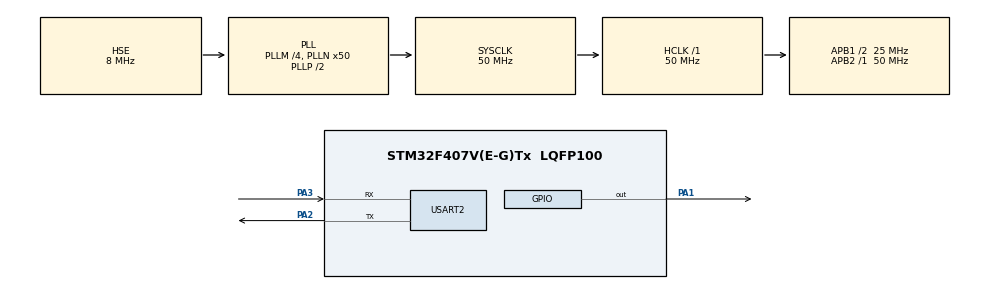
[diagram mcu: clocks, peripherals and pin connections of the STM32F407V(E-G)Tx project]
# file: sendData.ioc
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Mcu.Family=STM32F4
RCC.PLLSourceVirtual=RCC_PLLSOURCE_HSE
PH0-OSC_IN.Signal=RCC_OSC_IN
RCC.CortexFreq_Value=50000000
TIM6.Prescaler=50-1
VP_TIM6_VS_ClockSourceINT.Mode=Enable_Timer
RCC.APB1CLKDivider=RCC_HCLK_DIV2
RCC.SYSCLKSource=RCC_SYSCLKSOURCE_PLLCLK
ProjectManager.StackSize=0x400
PA3.Mode=Asynchronous
ProjectManager.TargetToolchain=STM32CubeIDE
RCC.HCLKFreq_Value=50000000
RCC.APB2TimFreq_Value=50000000
RCC.LSE_VALUE=32768
PA1.Signal=GPIO_Output
RCC.AHBFreq_Value=50000000
PH0-OSC_IN.Mode=HSE-External-Oscillator
RCC.HSE_VALUE=8000000
board=custom
RCC.VCOOutputFreq_Value=100000000
RCC.APB2Freq_Value=50000000
PH1-OSC_OUT.Signal=RCC_OSC_OUT
TIM6.Period=0xffff-1
Mcu.Name=STM32F407V(E-G)Tx
PA2.Signal=USART2_TX
PH1-OSC_OUT.Mode=HSE-External-Oscillator
RCC.48MHZClocksFreq_Value=25000000
RCC.SYSCLKFreq_VALUE=50000000
Mcu.Package=LQFP100
USART2.VirtualMode=VM_ASYNC
ProjectManager.HeapSize=0x200
RCC.HSI_VALUE=16000000
RCC.LSIState-ClockTree=RCC_LSI_ON
NVIC.PriorityGroup=NVIC_PRIORITYGROUP_4
RCC.PLLM=4
RCC.PLLN=50
RCC.APB1TimFreq_Value=50000000
PA2.Mode=Asynchronous
RCC.APB1Freq_Value=25000000
PA3.Signal=USART2_RX

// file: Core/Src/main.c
/* USER CODE BEGIN Header */
/**
  ******************************************************************************
  * @file           : main.c
  * @brief          : Main program body
  ******************************************************************************
  * @attention
  *
  * <h2><center>&copy; Copyright (c) 2022 STMicroelectronics.
  * All rights reserved.</center></h2>
  *
  * This software component is licensed by ST under BSD 3-Clause license,
  * the "License"; You may not use this file except in compliance with the
  * License. You may obtain a copy of the License at:
  *                        opensource.org/licenses/BSD-3-Clause
  *
  ******************************************************************************
  */
/* USER CODE END Header */
#include "main.h"

TIM_HandleTypeDef htim6;

UART_HandleTypeDef huart2;

/* USER CODE BEGIN PV */
int cont1=0;
int cont2=0;
/* USER CODE END PV */

void SystemClock_Config(void);
static void MX_GPIO_Init(void);
static void MX_TIM6_Init(void);
static void MX_USART2_UART_Init(void);

/* USER CODE BEGIN 0 */
//uint16_t Value_Buf[2];

void delay (uint16_t time)
{
	/* change your code here for the delay in microseconds */
	__HAL_TIM_SET_COUNTER(&htim6, 0);
	while ((__HAL_TIM_GET_COUNTER(&htim6))<time);
}
uint8_t Rh_byte1, Rh_byte2, Temp_byte1, Temp_byte2;
uint16_t SUM, RH, TEMP;

int Temperature = 0;
int Humidity = 0;
uint8_t Presence = 0;

void Set_Pin_Output (GPIO_TypeDef *GPIOx, uint16_t GPIO_Pin)
{
	GPIO_InitTypeDef GPIO_InitStruct = {0};
	GPIO_InitStruct.Pin = GPIO_Pin;
	GPIO_InitStruct.Mode = GPIO_MODE_OUTPUT_PP;
	GPIO_InitStruct.Speed = GPIO_SPEED_FREQ_LOW;
	HAL_GPIO_Init(GPIOx, &GPIO_InitStruct);
}

void Set_Pin_Input (GPIO_TypeDef *GPIOx, uint16_t GPIO_Pin)
{
	GPIO_InitTypeDef GPIO_InitStruct = {0};
	GPIO_InitStruct.Pin = GPIO_Pin;
	GPIO_InitStruct.Mode = GPIO_MODE_INPUT;
	GPIO_InitStruct.Pull = GPIO_PULLUP;
	HAL_GPIO_Init(GPIOx, &GPIO_InitStruct);
}
/*********************************** DHT11 FUNCTIONS ********************************************/

#define DHT11_PORT GPIOA
#define DHT11_PIN GPIO_PIN_1

void DHT11_Start (void)
{
	Set_Pin_Output (DHT11_PORT, DHT11_PIN);  // set the pin as output
	HAL_GPIO_WritePin (DHT11_PORT, DHT11_PIN, 0);   // pull the pin low
	delay(18000);   // wait for 18ms
    HAL_GPIO_WritePin (DHT11_PORT, DHT11_PIN, 1);   // pull the pin high
    delay(20);   // wait for 20us
	Set_Pin_Input(DHT11_PORT, DHT11_PIN);    // set as input
}

uint8_t DHT11_Check_Response (void)
{
	uint8_t Response = 0;
	delay (40);
	if (!(HAL_GPIO_ReadPin (DHT11_PORT, DHT11_PIN)))
	{
		delay (80);
		if ((HAL_GPIO_ReadPin (DHT11_PORT, DHT11_PIN))) Response = 1;
		else Response = -1; // 255
	}
	while ((HAL_GPIO_ReadPin (DHT11_PORT, DHT11_PIN)));   // wait for the pin to go low //travando aq

	return Response;
}

uint8_t DHT11_Read (void)
{
	uint8_t i,j;
	for (j=0;j<8;j++)
	{
		while (!(HAL_GPIO_ReadPin (DHT11_PORT, DHT11_PIN)));   // wait for the pin to go high
		delay (40);   // wait for 40 us
		if (!(HAL_GPIO_ReadPin (DHT11_PORT, DHT11_PIN)))   // if the pin is low
		{
			i&= ~(1<<(7-j));   // write 0
		}
		else i|= (1<<(7-j));  // if the pin is high, write 1
		while ((HAL_GPIO_ReadPin (DHT11_PORT, DHT11_PIN)));  // wait for the pin to go low
	}
	cont2++;
	return i;
}
void bufclr (char *buf)
{
	int len = strlen(buf);
	for (int i=0; i<len; i++) buf[i] = '\0';
}
/* USER CODE END 0 */

int main(void)
{

  /* MCU Configuration--------------------------------------------------------*/

  /* Reset of all peripherals, Initializes the Flash interface and the Systick. */
  HAL_Init();

  /* Configure the system clock */
  SystemClock_Config();

  /* Initialize all configured peripherals */
  MX_GPIO_Init();
  MX_TIM6_Init();
  MX_USART2_UART_Init();
  /* USER CODE BEGIN 2 */
  HAL_TIM_Base_Start(&htim6);
  char data[80];
    // estabelecendo a conexao
      HAL_UART_Transmit(&huart2,"AT+RST\r\n",8, HAL_MAX_DELAY);
      HAL_UART_Transmit(&huart2,"AT\r\n",4, HAL_MAX_DELAY);
      HAL_UART_Transmit(&huart2,"AT+CWMODE=1\r\n",13, HAL_MAX_DELAY);
      //HAL_UART_Transmit(&huart2,"AT+CWQAP\r\n",10, HAL_MAX_DELAY);
      sprintf (data, "AT+CWJAP=\"%s\",\"%s\"\r\n", "IME-Servicos", "");
      //sprintf (data, "AT+CWJAP=\"%s\"\r\n", "Nicolle");
      //sprintf(data, "AT+CWJAP=\"%s\",\"%s\"\r\n", "teste","12345678");
      HAL_UART_Transmit(&huart2,data,strlen(data), HAL_MAX_DELAY);
      HAL_UART_Transmit(&huart2,"AT+CIPMUX=0\r\n",13, HAL_MAX_DELAY);
      int contt=0;
      contt++;
  /* USER CODE END 2 */

  /* Infinite loop */
  while (1)
  {

    /* USER CODE BEGIN 3 */
	  /********************** DHT11 *********************/
	  DHT11_Start();
	  cont1++;
	  Presence = DHT11_Check_Response();
	  cont1++;
	  Rh_byte1 = DHT11_Read ();
	  Rh_byte2 = DHT11_Read ();
	  Temp_byte1 = DHT11_Read ();
	  Temp_byte2 = DHT11_Read ();
	  SUM = DHT11_Read();

	  TEMP = Temp_byte1;
	  RH = Rh_byte1;

	  Temperature = (int) TEMP;
	  Humidity = (int) RH;
	  char local_buf[500] = {0};
	  	  		  	char local_buf2[30] = {0};
	  	  		  	char local_buf3[50] = {0};
	  	  		  	char field_buf[200] = {0};
	  	  		  uint16_t value[2];
	  	  		  value[0] = TEMP; //temp
	  	  		  value[1] = RH; //umid
	  	  		  //value[0] = value[0]+1; //temp
	  	  		  //value[1] = value[1]+2; //umid
	  	  			sprintf (local_buf3, "AT+CIPSTART=\"TCP\",\"184.106.153.149\",80\r\n");
	  	  		   // HAL_Delay(3000);

	  	  		    HAL_UART_Transmit(&huart2,(uint8_t*)"AT+CIPSTART=\"TCP\",\"184.106.153.149\",80\r\n",sizeof("AT+CIPSTART=\"TCP\",\"184.106.153.149\",80\r\n")-1, HAL_MAX_DELAY);

	  	  		    HAL_Delay(500);

	  	  		  	sprintf (local_buf, "GET /update?api_key=D5ESDZQZA2Y2UY2C");
	  	  		  	for (int i=0; i<2; i++)
	  	  		  	{
	  	  		  		sprintf(field_buf, "&field%d=%u",i+1, value[i]);
	  	  		  		strcat(local_buf, field_buf);
	  	  		  	}

	  	  		  	strcat(local_buf, "\r\n");
	  	  		  	int len = strlen(local_buf);

	  	  		  	sprintf (local_buf2, "AT+CIPSEND=%d\r\n", len);
	  	  		    HAL_UART_Transmit(&huart2,local_buf2,strlen(local_buf2), HAL_MAX_DELAY);
	  	  		    HAL_Delay(500);
	  	  		    HAL_UART_Transmit(&huart2,local_buf,strlen(local_buf), HAL_MAX_DELAY);
	  	  		    HAL_Delay(500);

	  	  		  	bufclr(local_buf);
	  	  		  	bufclr(local_buf2);
	  	  		    HAL_Delay(15000);//delay necessario para atualizar
	  	  		    int cont=0;
	  	  		    cont++;
  }
  /* USER CODE END 3 */
}

void SystemClock_Config(void)
{
  RCC_OscInitTypeDef RCC_OscInitStruct = {0};
  RCC_ClkInitTypeDef RCC_ClkInitStruct = {0};

  /** Configure the main internal regulator output voltage
  */
  __HAL_RCC_PWR_CLK_ENABLE();
  __HAL_PWR_VOLTAGESCALING_CONFIG(PWR_REGULATOR_VOLTAGE_SCALE1);
  /** Initializes the RCC Oscillators according to the specified parameters
  * in the RCC_OscInitTypeDef structure.
  */
  RCC_OscInitStruct.OscillatorType = RCC_OSCILLATORTYPE_HSE;
  RCC_OscInitStruct.HSEState = RCC_HSE_ON;
  RCC_OscInitStruct.PLL.PLLState = RCC_PLL_ON;
  RCC_OscInitStruct.PLL.PLLSource = RCC_PLLSOURCE_HSE;
  RCC_OscInitStruct.PLL.PLLM = 4;
  RCC_OscInitStruct.PLL.PLLN = 50;
  RCC_OscInitStruct.PLL.PLLP = RCC_PLLP_DIV2;
  RCC_OscInitStruct.PLL.PLLQ = 4;
  if (HAL_RCC_OscConfig(&RCC_OscInitStruct) != HAL_OK)
  {
    Error_Handler();
  }
  /** Initializes the CPU, AHB and APB buses clocks
  */
  RCC_ClkInitStruct.ClockType = RCC_CLOCKTYPE_HCLK|RCC_CLOCKTYPE_SYSCLK
                              |RCC_CLOCKTYPE_PCLK1|RCC_CLOCKTYPE_PCLK2;
  RCC_ClkInitStruct.SYSCLKSource = RCC_SYSCLKSOURCE_PLLCLK;
  RCC_ClkInitStruct.AHBCLKDivider = RCC_SYSCLK_DIV1;
  RCC_ClkInitStruct.APB1CLKDivider = RCC_HCLK_DIV2;
  RCC_ClkInitStruct.APB2CLKDivider = RCC_HCLK_DIV1;

  if (HAL_RCC_ClockConfig(&RCC_ClkInitStruct, FLASH_LATENCY_1) != HAL_OK)
  {
    Error_Handler();
  }
}

static void MX_TIM6_Init(void)
{

  TIM_MasterConfigTypeDef sMasterConfig = {0};

  htim6.Instance = TIM6;
  htim6.Init.Prescaler = 50-1;
  htim6.Init.CounterMode = TIM_COUNTERMODE_UP;
  htim6.Init.Period = 0xffff-1;
  htim6.Init.AutoReloadPreload = TIM_AUTORELOAD_PRELOAD_DISABLE;
  if (HAL_TIM_Base_Init(&htim6) != HAL_OK)
  {
    Error_Handler();
  }
  sMasterConfig.MasterOutputTrigger = TIM_TRGO_RESET;
  sMasterConfig.MasterSlaveMode = TIM_MASTERSLAVEMODE_DISABLE;
  if (HAL_TIMEx_MasterConfigSynchronization(&htim6, &sMasterConfig) != HAL_OK)
  {
    Error_Handler();
  }

}

static void MX_USART2_UART_Init(void)
{

  huart2.Instance = USART2;
  huart2.Init.BaudRate = 115200;
  huart2.Init.WordLength = UART_WORDLENGTH_8B;
  huart2.Init.StopBits = UART_STOPBITS_1;
  huart2.Init.Parity = UART_PARITY_NONE;
  huart2.Init.Mode = UART_MODE_TX_RX;
  huart2.Init.HwFlowCtl = UART_HWCONTROL_NONE;
  huart2.Init.OverSampling = UART_OVERSAMPLING_16;
  if (HAL_UART_Init(&huart2) != HAL_OK)
  {
    Error_Handler();
  }

}

static void MX_GPIO_Init(void)
{
  GPIO_InitTypeDef GPIO_InitStruct = {0};

  /* GPIO Ports Clock Enable */
  __HAL_RCC_GPIOH_CLK_ENABLE();
  __HAL_RCC_GPIOA_CLK_ENABLE();

  /*Configure GPIO pin Output Level */
  HAL_GPIO_WritePin(GPIOA, GPIO_PIN_1, GPIO_PIN_RESET);

  /*Configure GPIO pin Output Level */

  /*Configure GPIO pin : PA1 */
  GPIO_InitStruct.Pin = GPIO_PIN_1;
  GPIO_InitStruct.Mode = GPIO_MODE_OUTPUT_PP;
  GPIO_InitStruct.Pull = GPIO_NOPULL;
  GPIO_InitStruct.Speed = GPIO_SPEED_FREQ_LOW;
  HAL_GPIO_Init(GPIOA, &GPIO_InitStruct);

}

void Error_Handler(void)
{
  __disable_irq();
  while (1)
  {
  }
}

/************************ (C) COPYRIGHT STMicroelectronics *****END OF FILE****/
